# XMC4700 register map
Vendor: Infineon; File version: 1.0.2 (Reference Manual v1.0)
CPU: CM4 r2p0, little endian, MPU, FPU, 6 interrupt priority bits
Registers are 32-bit, read-write, reset 0x0 unless marked. A register's access mark holds for its fields unless they carry their own. Offsets are from the block's base; [hi:lo] are bit positions; {n}, {i} and the like mark numbered series; 'fields as' and 'values as' point back to an identical list.

## CCU80 — Capture Compare Unit 8 - Unit 0
Base 0x40020000
Same registers: CCU81 0x40024000
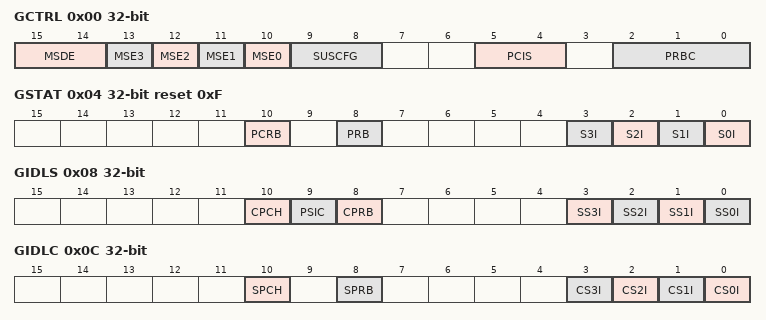
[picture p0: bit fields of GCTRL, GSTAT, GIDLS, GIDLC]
0x00 GCTRL — Global Control Register
  [15:14] MSDE — Multi Channel shadow transfer request configuration
    0=Only the shadow transfer for period and compare values is requested; 1=Shadow transfer for the compare, period and prescaler compare values is requested; 3=Shadow transfer for the compare, period, prescaler and dither compare values is requested
  [13] MSE3 — Slice 3 Multi Channel shadow transfer enable
    0=Shadow transfer can only be requested by SW; 1=Shadow transfer can be requested via SW and via the CCU8x.MCSS input
  [12] MSE2 — Slice 2 Multi Channel shadow transfer enable
    0=Shadow transfer can only be requested by SW; 1=Shadow transfer can be requested via SW and via the CCU8xMCSS input
  [11] MSE1 — Slice 1 Multi Channel shadow transfer enable
    values as MSE3
  [10] MSE0 — Slice 0 Multi Channel shadow transfer enable
    values as MSE3
  [9:8] SUSCFG — Suspend Mode Configuration
    0=Suspend request ignored. The module never enters in suspend; 1=Stops all the running slices immediately. Safe stop is not applied.; 2=Stops the block immediately and clamps all the outputs to PASSIVE state. Safe stop is applied.; 3=Waits for the roll over of each slice to stop and clamp the slices outputs. Safe stop is applied.
  [5:4] PCIS — Prescaler Input Clock Selection
    0=Module clock; 1=CCU8x.ECLKA; 2=CCU8x.ECLKB; 3=CCU8x.ECLKC
  [2:0] PRBC — Prescaler Clear Configuration
    0=SW only; {v}=GSTATThe register contains the status of the prescaler and each timer slice (idle mode or running)..PRB and prescaler registers are cleared when the Run Bit of CC{v+79} is cleared (v=1..4)
0x04 GSTAT ro reset 0xF — Global Status Register
  [10] PCRB — Parity Checker Run Bit
    0=Parity Checker is stopped; 1=Parity Checker is running
  [8] PRB — Prescaler Run Bit
    0=Prescaler is stopped; 1=Prescaler is running
  [n] S{n}I (n=0..3) — CC{n+80} IDLE status
    0=Running; 1=Idle
0x08 GIDLS wo — Global Idle Set
  [10] CPCH — Parity Checker Run bit clear
  [9] PSIC — Prescaler clear
  [8] CPRB — Prescaler# Run Bit Clear
  [n] SS{n}I (n=0..3) — CC{n+80} IDLE mode set
0x0C GIDLC wo — Global Idle Clear
  [10] SPCH — Parity Checker run bit set
  [8] SPRB — Prescaler Run Bit Set
  [n] CS{n}I (n=0..3) — CC{n+80} IDLE mode clear
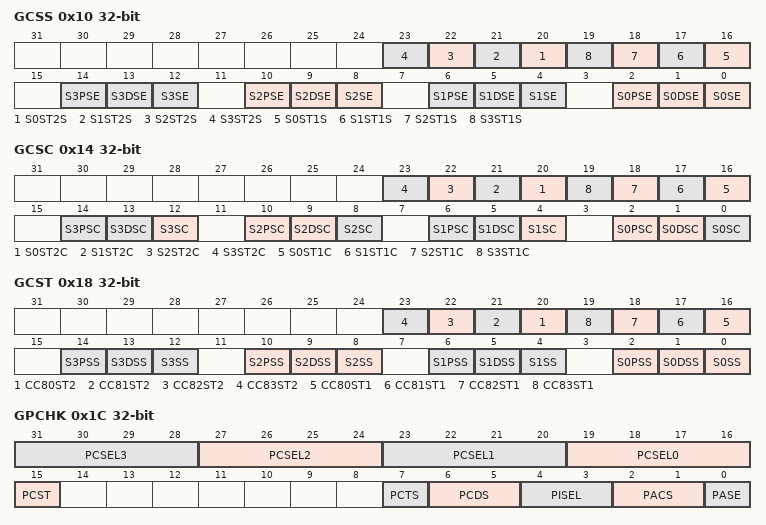
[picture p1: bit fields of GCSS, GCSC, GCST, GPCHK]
0x10 GCSS wo — Global Channel Set
  [n+20] S{n}ST2S (n=0..3) — Slice {n} status bit 2 set
  [n+16] S{n}ST1S (n=0..3) — Slice {n} status bit 1 set
  [4n+2] S{n}PSE (n=0..3) — Slice {n} Prescaler shadow transfer set enable
  [4n+1] S{n}DSE (n=0..3) — Slice {n} Dither shadow transfer set enable
  [4n] S{n}SE (n=0..3) — Slice {n} shadow transfer set enable
0x14 GCSC wo — Global Channel Clear
  [n+20] S{n}ST2C (n=0..3) — Slice {n} status bit 2 clear
  [n+16] S{n}ST1C (n=0..3) — Slice {n} status bit 1 clear
  [4n+2] S{n}PSC (n=0..3) — Slice {n} Prescaler shadow transfer clear
  [4n+1] S{n}DSC (n=0..3) — Slice {n} Dither shadow transfer clear
  [12] S3SC — Slice 3 shadow transfer clear
  [8] S2SC — Slice 2 shadow transfer clear
  [4] S1SC — Slice 1 shadow transfer clear
  [0] S0SC — Slice 0 shadow transfer request clear
0x18 GCST ro — Global Channel status
  [n-60] CC{n}ST2 (n=80..83) — Slice {n-80} compare channel 2 status bit
  [n-64] CC{n}ST1 (n=80..83) — Slice {n-80} compare channel 1 status bit
  [4n+2] S{n}PSS (n=0..3) — Slice {n} Prescaler shadow transfer status
    0=Prescaler shadow transfer has not been requested; 1=Prescaler shadow transfer has been requested
  [4n+1] S{n}DSS (n=0..3) — Slice {n} Dither shadow transfer status
    0=Dither shadow transfer has not been requested; 1=Dither shadow transfer has been requested
  [4n] S{n}SS (n=0..3) — Slice {n} shadow transfer status
    0=Shadow transfer has not been requested; 1=Shadow transfer has been requested
0x1C GPCHK access per field — Parity Checker Configuration
  [4n+19:4n+16] PCSEL{n} rw (n=0..3) — Parity Checker Slice {n} output selection
  [15] PCST ro — Parity Checker XOR status
  [7] PCTS rw — Parity Checker type selector
    0=Even parity enabled; 1=Odd parity enabled
  [6:5] PCDS rw — Parity Checker Delay Input Selector
    0=CCU8x.IGBTA; 1=CCU8x.IGBTB; 2=CCU8x.IGBTC; 3=CCU8x.IGBTD
  [4:3] PISEL rw — Driver Input signal selector
    0=CC8x.GP01 - driver output is connected to event 1 of slice 0; 1=CC8x.GP11 - drive output is connected to event 1 of slice 1; 2=CC8x.GP21 - driver output is connected to event 1 of slice 2; 3=CC8x.GP31 - driver output is connected to event 1 of slice 3
  [2:1] PACS rw — Parity Checker Automatic start/stop selector
    {v}=CC{v+80} (v=0..3)
  [0] PASE rw — Parity Checker Automatic start/stop
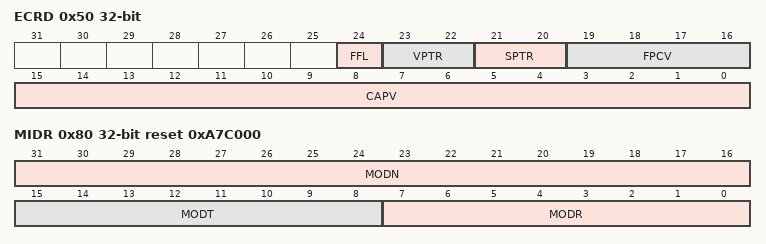
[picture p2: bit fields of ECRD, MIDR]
0x50 ECRD ro read-has-side-effects — Extended Capture Mode Read
  [24] FFL — Full Flag
    0=No new value was captured into this register; 1=A new value has been captured into this register
  [23:22] VPTR — Capture register pointer
    {v}=Capture register {v} (v=0..3)
  [21:20] SPTR — Slice pointer
    {v}=CC{v+80} (v=0..3)
  [19:16] FPCV — Prescaler Capture value
  [15:0] CAPV — Timer Capture Value
0x80 MIDR ro reset 0xA7C000 (reset mask 0xFFFFFF00) — Module Identification
  [31:16] MODN — Module Number
  [15:8] MODT — Module Type
  [7:0] MODR — Module Revision

## Notices in the file
Copyright (c) 2016, Infineon Technologies AG
All rights reserved.
Redistribution and use in source and binary forms, with or without modification,are permitted provided that the
following conditions are met:
Redistributions of source code must retain the above copyright notice, this list of conditions and the following
disclaimer.
Redistributions in binary form must reproduce the above copyright notice, this list of conditions and the following
disclaimer in the documentation and/or other materials provided with the distribution.
Neither the name of the copyright holders nor the names of its contributors may be used to endorse or promote
products derived from this software without specific prior written permission.
THIS SOFTWARE IS PROVIDED BY THE COPYRIGHT HOLDERS AND CONTRIBUTORS "AS IS" AND ANY EXPRESS OR IMPLIED WARRANTIES,
INCLUDING, BUT NOT LIMITED TO, THE IMPLIED WARRANTIES OF MERCHANTABILITY AND FITNESS FOR A PARTICULAR PURPOSE ARE
DISCLAIMED. IN NO EVENT SHALL THE COPYRIGHT HOLDER OR CONTRIBUTORS BE LIABLE  FOR ANY DIRECT, INDIRECT, INCIDENTAL,
SPECIAL, EXEMPLARY, OR CONSEQUENTIAL DAMAGES (INCLUDING, BUT NOT LIMITED TO, PROCUREMENT OF SUBSTITUTE GOODS OR
SERVICES; LOSS OF USE, DATA, OR PROFITS; OR BUSINESS INTERRUPTION) HOWEVER CAUSED AND ON ANY THEORY OF LIABILITY,
WHETHER IN CONTRACT, STRICT LIABILITY,OR TORT (INCLUDING NEGLIGENCE OR OTHERWISE) ARISING IN ANY WAY OUT OF THE USE
OF THIS SOFTWARE, EVEN IF ADVISED OF THE POSSIBILITY OF SUCH DAMAGE.
